# I2C register map
Vendor: Texas Instruments
Peripheral module from a debugger description file (folder am335x).
Registers are 32-bit, access per field, no defined reset value unless marked. A register's access mark holds for its fields unless they carry their own. Offsets are as the file gives them; lines under a group give offsets from that group; [hi:lo] are bit positions; {n}, {i} and the like mark numbered series; 'fields as' and 'values as' point back to an identical list; <NAME> marks a mode.

## I2C (part 1 of 2)
0x38 I2C_DMARXENABLE_SET — The 1-bit field enables a receive DMA request. Writing a 1 to this field will set it to 1. Writing a 0 will have no effect, that is, the register value is not modified. Note that the I2C_BUF.RDMA_EN field is the global (slave) DMA enabler, and that it is disabled by default. The I2C_BUF.RDMA_EN field should also be set to 1 to enable a receive DMA request.
  [0] DMARX_ENABLE_SET rw — Receive DMA channel enable set.
0x3C I2C_DMATXENABLE_SET — The 1-bit field enables a transmit DMA request. Writing a 1 to this field will set it to 1. Writing a 0 will have no effect, that is, the register value is not modified. Note that the I2C_BUF.XDMA_EN field is the global (slave) DMA enabler, and that it is disabled by default. The I2C_BUF.XDMA_EN field should also be set to 1 to enable a transmit DMA request.
  [0] DMATX_TRANSMIT_SET rw — Transmit DMA channel enable set.
0x40 I2C_DMARXENABLE_CLR — The 1-bit field disables a receive DMA request. Writing a 1 to a bit will clear it to 0. Another result of setting to 1 the DMARX_ENABLE_CLEAR field, is the reset of the DMA RX request and wakeup lines. Writing a 0 will have no effect, that is, the register value is not modified.
  [0] DMARX_ENABLE_CLEAR rw — Receive DMA channel enable clear.
0x44 I2C_DMATXENABLE_CLR — The 1-bit field disables a transmit DMA request. Writing a 1 to a bit will clear it to 0. Another result of setting to 1 the DMATX_ENABLE_CLEAR field, is the reset of the DMA TX request and wakeup lines. Writing a 0 will have no effect, that is, the register value is not modified.
  [0] DMARX_ENABLE_CLEAR rw — Receive DMA channel enable clear.
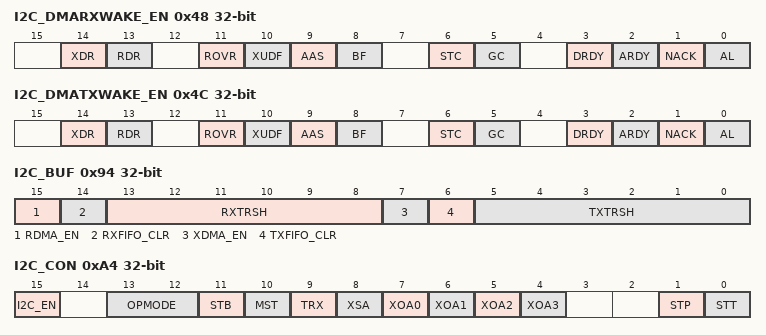
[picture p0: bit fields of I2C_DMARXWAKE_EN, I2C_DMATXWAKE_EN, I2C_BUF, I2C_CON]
0x48 I2C_DMARXWAKE_EN — All 1-bit fields enable a specific (synchronous) DMA request source to generate an asynchronous wakeup (on the appropriate swakeup line). Note that the I2C_SYSC.ENAWAKEUP field is the global (slave) wakeup enabler, and that it is disabled by default.
  [14] XDR rw — Transmit draining wakeup set.
  [13] RDR rw — Receive draining wakeup set.
  [11] ROVR rw — Receive overrun wakeup set.
  [10] XUDF rw — Transmit underflow wakeup set.
  [9] AAS rw — Address as slave IRQ wakeup set.
  [8] BF rw — Bus free IRQ wakeup set.
  [6] STC rw — Start condition IRQ wakeup set.
  [5] GC rw — General call IRQ wakeup set.
  [3] DRDY rw — Receive/transmit data ready IRQ wakeup set.
  [2] ARDY rw — Register access ready IRQ wakeup set.
  [1] NACK rw — No acknowledgment IRQ wakeup set.
  [0] AL rw — Arbitration lost IRQ wakeup set.
0x4C I2C_DMATXWAKE_EN — All 1-bit fields enable a specific (synchronous) DMA request source to generate an asynchronous wakeup (on the appropriate swakeup line). Note that the I2C_SYSC.ENAWAKEUP field is the global (slave) wakeup enabler, and that it is disabled by default.
  fields as I2C_DMARXWAKE_EN
0x90 I2C_SYSS
  [0] RDONE rw — Reset done bit. This read-only bit indicates the state of the reset in case of hardware reset, global software reset (I2C_SYSC.SRST) or partial software reset (I2C_CON.I2C_EN). The module must receive all its clocks before it can grant a reset-completed status. Value after reset is low.
0x94 I2C_BUF — This read/write register enables DMA transfers and allows the configuration of FIFO thresholds for the FIFO management (see the FIFO Management subsection).
  [15] RDMA_EN rw — Receive DMA channel enable. When this bit is set to 1, the receive DMA channel is enabled and the receive data ready status bit (I2C_IRQSTATUS_RAW: RRDY) is forced to 0 by the core. Value after reset is low.
  [14] RXFIFO_CLR rw — Receive FIFO clear. When set, receive FIFO is cleared (hardware reset for RX FIFO generated). This bit is automatically reset by the hardware. During reads, it always returns 0. Value after reset is low.
  [13:8] RXTRSH rw — Threshold value for FIFO buffer in RX mode. The receive threshold value is used to specify the trigger level for data receive transfers. The value is specified from the Interface/OCP point of view. Value after reset is 00h. For the FIFO management description, see the FIFO Management subsection. Note 1: programmed threshold cannot exceed the actual depth of the FIFO. Note 2: the threshold must not be changed while a transfer is in progress (after STT was configured or after the module was addressed as a slave).
  [7] XDMA_EN rw — Transmit DMA channel enable. When this bit is set to 1, the transmit DMA channel is enabled and the transmit data ready status (I2C_IRQSTATUS_RAW: XRDY) bit is forced to 0 by the core. Value after reset is low.
  [6] TXFIFO_CLR rw — Transmit FIFO clear. When set, transmit FIFO is cleared (hardware reset for TX FIFO). This bit is automatically reset by the hardware. During reads, it always returns 0. Value after reset is low.
  [5:0] TXTRSH rw — Threshold value for FIFO buffer in TX mode. The Transmit Threshold value is used to specify the trigger level for data transfers. The value is specified from the OCP point of view. Value after reset is 00h Note 1: programmed threshold cannot exceed the actual depth of the FIFO. Note 2: the threshold must not be changed while a transfer is in progress (after STT was configured or after the module was addressed as a slave).
0x98 I2C_CNT — CAUTION: During an active transfer phase (between STT having been set to 1 and reception of ARDY), no modification must be done in this register. Changing it may result in an unpredictable behavior. This read/write register is used to control the numbers of bytes in the I2C data payload.
  [15:0] DCOUNT rw — Data count. I2C Master Mode only (receive or transmit; F/S). This 16-bit countdown counter decrements by 1 for every byte received or sent through the I2C interface. A write initializes DCOUNT to a saved initial value. A read returns the number of bytes that are yet to be received or sent. A read into DCOUNT returns the initial value only before a start condition and after a stop condition. When DCOUNT reaches 0, the core generates a stop condition if a stop condition was specified (I2C_CON.STP = 1) and the ARDY status flag is set to 1 in the I2C_IRQSTATUS_RAW register. Note that DCOUNT must not be reconfigured after I2C_CON.STT was enabled and before ARDY is received. Note 1: In case of I2C mode of operation, if I2C_CON.STP = 0, then the I2C asserts SCL = 0 when DCOUNT reaches 0. The CPU can then reprogram DCOUNT to a new value and resume sending or receiving data with a new start condition (restart). This process repeats until the CPU sets to 1 the I2C_CON.STP bit. The ARDY flag is set each time DCOUNT reaches 0 and DCOUNT is reloaded to its initial value. Values after reset are low (all 16 bits). Note 2: Since for DCOUNT = 0, the transfer length is 65536, the module does not allow the possibility to initiate zero data bytes transfers.
0x9C I2C_DATA — This register is the entry point for the local host to read data from or write data to the FIFO buffer.
  [7:0] DATA rw — Transmit/Receive data FIFO endpoint. When read, this register contains the received I2C data. When written, this register contains the byte value to transmit over the I2C data. In SYSTEST loop back mode (I2C_SYSTEST: TMODE = 11), this register is also the entry/receive point for the data. Values after reset are unknown (all 8-bits). Note: A read access, when the buffer is empty, returns the previous read data value. A write access, when the buffer is full, is ignored. In both events, the FIFO pointers are not updated and an Access Error (AERR) Interrupt is generated.
0xA4 I2C_CON — During an active transfer phase (between STT having been set to 1 and reception of ARDY), no modification must be done in this register (except STP enable). Changing it may result in an unpredictable behavior.
  [15] I2C_EN rw — I2C module enable. When this bit is cleared to 0, the I2C controller is not enabled and reset. When 0, receive and transmit FIFOs are cleared and all status bits are set to their default values. All configuration registers (I2C_IRQENABLE_SET, I2C_IRQWAKE_SET, I2C_BUF, I2C_CNT, I2C_CON, I2C_OA, I2C_SA, I2C_PSC, I2C_SCLL and I2C_SCLH) are not reset, they keep their initial values and can be accessed. The CPU must set this bit to 1 for normal operation. Value after reset is low.
  [13:12] OPMODE rw — Operation mode selection. These two bits select module operation mode. Value after reset is 00.
  [11] STB rw — Start byte mode (I2C master mode only). The start byte mode bit is set to 1 by the CPU to configure the I2C in start byte mode (I2C_SA = 0000 0001). See the Philips I2C spec for more details [1]. Value after reset is low.
  [10] MST rw — Master/slave mode (I2C mode only). When this bit is cleared, the I2C controller is in the slave mode and the serial clock (SCL) is received from the master device. When this bit is set, the I2C controller is in the master mode and generates the serial clock. Note: This bit is automatically cleared at the end of the transfer on a detected stop condition, in case of arbitration lost or when the module is configured as a master but addressed as a slave by an external master. Value after reset is low.
  [9] TRX rw — Transmitter/receiver mode (i2C master mode only). When this bit is cleared, the I2C controller is in the receiver mode and data on data line SDA is shifted into the receiver FIFO and can be read from I2C_DATA register. When this bit is set, the I2C controller is in the transmitter mode and the data written in the transmitter FIFO via I2C_DATA is shifted out on data line SDA. Value after reset is low. The operating modes are defined as follows: MST = 0, TRX = x, Operating Mode = Slave receiver. MST = 0, TRX = x, Operating Mode = Slave transmitter. MST = 1, TRX = 0, Operating Modes = Master receiver. MST = 1, TRX = 0, Operating Modes = Master transmitter.
  [8] XSA rw — Expand slave address. (I2C mode only). When set, this bit expands the slave address to 10-bit. Value after reset is low.
  [7] XOA0 rw — Expand own address 0. (I2C mode only). When set, this bit expands the base own address (OA0) to 10-bit. Value after reset is low.
  [6] XOA1 rw — Expand own address 1. (I2C mode only). When set, this bit expands the first alternative own address (OA1) to 10-bit. Value after reset is low.
  [5] XOA2 rw — Expand own address 2. (I2C mode only). When set, this bit expands the second alternative own address (OA2) to 10-bit. Value after reset is low.
  [4] XOA3 rw — Expand own address 3. When set, this bit expands the third alternative own address (OA3) to 10-bit. Value after reset is low.
  [1] STP rw — Stop condition (I2C master mode only). This bit can be set to a 1 by the CPU to generate a stop condition. It is reset to 0 by the hardware after the stop condition has been generated. The stop condition is generated when DCOUNT passes 0. When this bit is not set to 1 before the end of the transfer (DCOUNT = 0), the stop condition is not generated and the SCL line is hold to 0 by the master, which can re-start a new transfer by setting the STT bit to 1. Value after reset is low
  [0] STT rw — Start condition (I2C master mode only). This bit can be set to a 1 by the CPU to generate a start condition. It is reset to 0 by the hardware after the start condition has been generated. The start/stop bits can be configured to generate different transfer formats. Value after reset is low. Note: DCOUNT is data count value in I2C_CNT register. STT = 1, STP = 0, Conditions = Start, Bus Activities = S-A-D. STT = 0, STP = 1, Conditions = Stop, Bus Activities = P. STT = 1, STP = 1, Conditions = Start-Stop (DCOUNT=n), Bus Activities = S-A-D..(n)..D-P. STT = 1, STP = 0, Conditions = Start (DCOUNT=n), Bus Activities = S-A-D..(n)..D.
0xA8 I2C_OA — CAUTION: During an active transfer phase (between STT having been set to 1 and reception of ARDY), no modification must be done in this register. Changing it may result in an unpredictable behavior. This register is used to specify the module s base I2C 7-bit or 10-bit address (base own address).
  [9:0] OA rw — Own address. This field specifies either: A 10-bit address coded on OA [9:0] when XOA (Expand Own Address, I2C_CON[7]) is set to 1. or A 7-bit address coded on OA [6:0] when XOA (Expand Own Address, I2C_CON[7]) is cleared to 0. In this case, OA [9:7] bits must be cleared to 000 by application software. Value after reset is low (all 10 bits).
0xAC I2C_SA — CAUTION: During an active transfer phase (between STT having been set to 1 and reception of ARDY), no modification must be done in this register. Changing it may result in an unpredictable behavior. This register is used to specify the addressed I2C module 7-bit or 10-bit address (slave address).
  [9:0] SA rw — Slave address. This field specifies either: A 10-bit address coded on SA [9:0] when XSA (Expand Slave Address, I2C_CON[8]) is set to 1. or A 7-bit address coded on SA [6:0] when XSA (Expand Slave Address, I2C_CON[8]) is cleared to 0. In this case, SA [9:7] bits must be cleared to 000 by application software. Value after reset is low (all 10 bits).
0xB0 I2C_PSC — CAUTION: During an active mode (I2C_EN bit in I2C_CON register is set to 1), no modification must be done in this register. Changing it may result in an unpredictable behavior. This register is used to specify the internal clocking of the I2C peripheral core.
  [7:0] PSC rw — Fast/Standard mode prescale sampling clock divider value. The core uses this 8-bit value to divide the system clock (SCLK) and generates its own internal sampling clock (ICLK) for Fast and Standard operation modes. The core logic is sampled at the clock rate of the system clock for the module divided by (PSC + 1). Value after reset is low (all 8 bits).
0xB4 I2C_SCLL — CAUTION: During an active mode (I2C_EN bit in I2C_CON register is set to 1), no modification must be done in this register. Changing it may result in an unpredictable behavior. This register is used to determine the SCL low time value when master.
  [7:0] SCLL rw — Fast/Standard mode SCL low time. I2C master mode only, (FS). This 8-bit value is used to generate the SCL low time value (tLOW) when the peripheral is operated in master mode. tLOW = (SCLL + 7) * ICLK time period, Value after reset is low (all 8 bits).
0xB8 I2C_SCLH — CAUTION: During an active mode (I2C_EN bit in I2C_CON register is set to 1), no modification must be done in this register. Changing it may result in an unpredictable behavior. This register is used to determine the SCL high time value when master.
  [7:0] SCLH rw — Fast/Standard mode SCL low time. I2C master mode only, (FS). This 8-bit value is used to generate the SCL high time value (tHIGH) when the peripheral is operated in master mode. - tHIGH = (SCLH + 5) * ICLK time period. Value after reset is low (all 8 bits).
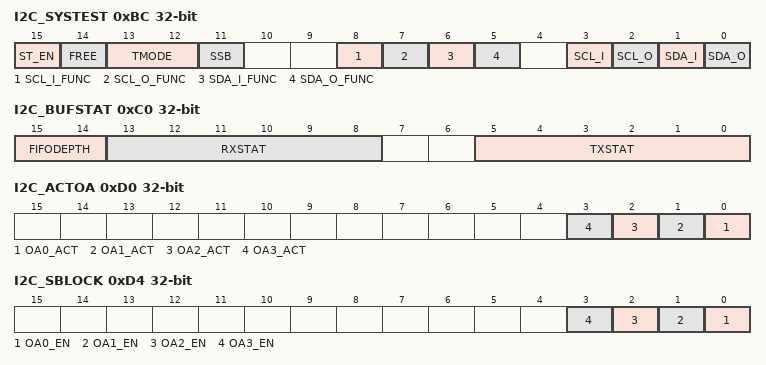
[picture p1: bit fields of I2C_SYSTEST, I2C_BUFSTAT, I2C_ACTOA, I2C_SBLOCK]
0xBC I2C_SYSTEST — CAUTION: Never enable this register for normal I2C operation This register is used to facilitate system-level tests by overriding some of the standard functional features of the peripheral. It allows testing of SCL counters, controlling the signals that connect to I/O pins, or creating digital loop-back for self-test when the module is configured in system test (SYSTEST) mode. It also provides stop/non-stop functionality in the debug mode.
  [15] ST_EN rw — System test enable. This bit must be set to 1 to permit other system test registers bits to be set. Value after reset is low.
  [14] FREE rw — Free running mode (on breakpoint). This bit is used to determine the state of the I2C controller when a breakpoint is encountered in the HLL debugger. Note: This bit can be set independently of ST_EN value. FREE = 0: the I2C controller stops immediately after completion of the on-going bit transfer. Stopping the transfer is achieved by forcing the SCL line low. Note that in this case there will be no status register updates. FREE = 1: the I2C interface runs free. When Suspend indication will be asserted, there will be no accesses on the OCP Interface (the CPU is in debug mode) and consequently the FIFOs will reach full/empty state (according to RX or TX modes) and the I2C SDA line will be kept low. Note that the status registers will be updated, but no DMA, IRQ or WakeUp will be generated. The status registers likely to be updated in this mode are: I2C_IRQSTATUS_RAW.XRDY, I2C_IRQSTATUS_RAW.RRDY, I2C_IRQSTATUS_RAW.XUDF, I2C_IRQSTATUS_RAW.ROVR, I2C_IRQSTATUS_RAW.ARDY and I2C_IRQSTATUS_RAW.NACK. Value after reset is low.
  [13:12] TMODE rw — Test mode select. In normal functional mode (ST_EN = 0), these bits are don't care. They are always read as 00 and a write is ignored. In system test mode (ST_EN = 1), these bits can be set according to the following table to permit various system tests. Values after reset are low (2 bits). SCL counter test mode: in this mode, the SCL pin is driven with a permanent clock as if mastered with the parameters set in the I2C_PSC, I2C_SCLL, and I2C_SCLH registers. Loop back mode: in the master transmit mode only, data transmitted out of the I2C_DATA register (write action) is received in the same I2C_DATA register via an internal path through the FIFO buffer. The DMA and interrupt requests are normally generated if enabled. SDA/SCL IO mode: in this mode, the SCL IO and SDA IO are controlled via the I2C_SYSTEST [5:0] register bits.
  [11] SSB rw — Set status bits. Writing 1 into this bit also sets the 6 read/clear-only status bits contained in I2C_IRQSTATUS_RAW register (bits 5:0) to 1. Writing 0 into this bit doesn't clear status bits that are already set; only writing 1 into a set status bit can clear it (see I2C_IRQSTATUS_RAW operation). This bit must be cleared prior attempting to clear a status bit. Value after reset is low.
  [8] SCL_I_FUNC ro — SCL line input value (functional mode). This read-only bit returns the logical state taken by the SCL line (either 1 or 0). It is active both in functional and test mode. Value after reset is low.
  [7] SCL_O_FUNC ro — SCL line output value (functional mode). This read-only bit returns the value driven by the module on the SCL line (either 1 or 0). It is active both in functional and test mode. Value after reset is low.
  [6] SDA_I_FUNC ro — SDA line input value (functional mode). This read-only bit returns the logical state taken by the SDA line (either 1 or 0). It is active both in functional and test mode. Value after reset is low.
  [5] SDA_O_FUNC ro — SDA line output value (functional mode). This read-only bit returns the value driven by the module on the SDA line (either 1 or 0). It is active both in functional and test mode. Value after reset is low.
  [3] SCL_I ro — SCL line sense input value. In normal functional mode (ST_EN = 0), this read-only bit always reads 0. In system test mode (ST_EN = 1 and TMODE = 11), this read-only bit returns the logical state taken by the SCL line (either 1 or 0). Value after reset is low.
  [2] SCL_O ro — SCL line drive output value. In normal functional mode (ST_EN = 0), this bit is don't care. It always reads 0 and a write is ignored. In system test mode (ST_EN = 1 and TMODE = 11), a 0 forces a low level on the SCL line and a 1 puts the I2C output driver to a high-impedance state. Value after reset is low.
  [1] SDA_I ro — SDA line sense input value. In normal functional mode (ST_EN = 0), this read-only bit always reads 0. In system test mode (ST_EN = 1 and TMODE = 11), this read-only bit returns the logical state taken by the SDA line (either 1 or 0). Value after reset is low.
  [0] SDA_O ro — SDA line drive output value. In normal functional mode (ST_EN = 0), this bit is don't care. It reads as 0 and a write is ignored. In system test mode (ST_EN = 1 and TMODE = 11), a 0 forces a low level on the SDA line and a 1 puts the I2C output driver to a high-impedance state. Value after reset is low.
0xC0 I2C_BUFSTAT ro — This read-only register reflects the status of the internal buffers for the FIFO management (see the FIFO Management subsection).
  [15:14] FIFODEPTH — Internal FIFO buffers depth. This read-only bit indicates the internal FIFO buffer depth. Value after reset is given by the boundary module generic parameter.
  [13:8] RXSTAT — RX buffer status. This read-only field indicates the number of bytes to be transferred from the FIFO at the end of the I2C transfer (when RDR is asserted). It corresponds to the level indication of the RX FIFO (number of written locations). Value after reset is 0.
  [5:0] TXSTAT — TX buffer status. This read-only field indicates the number of data bytes still left to be written in the TX FIFO (it s equal with the initial value of I2C_CNT.DCOUNT minus the number of data bytes already written in the TX FIFO through the OCP Interface). Value after reset is equal with 0.
0xC4 I2C_OA1 — CAUTION: During an active transfer phase (between STT has been set to 1 and receiving of ARDY), no modification must be done in this register. Changing it may result in an unpredictable behavior. This register is used to specify the first alternative I2C 7-bit or 10-bit address (own address 1 - OA1).
  [9:0] OA1 rw — Own address 1. This field specifies either: A 10-bit address coded on OA1 [9:0] when XOA1 (Expand Own Address 1 - XOA1, I2C_CON[6]) is set to 1. A 7-bit address coded on OA1 [6:0] when XOA1 (Expand Own Address 1 XOA1, I2C_CON[6]) is cleared to 0. In this case, OA1 [9:7] bits must be cleared to 000 by application software. Value after reset is low (all 10 bits).
0xC8 I2C_OA2 — CAUTION: During an active transfer phase (between STT has been set to 1 and receiving of ARDY), no modification must be done in this register. Changing it may result in an unpredictable behavior. This register is used to specify the first alternative I2C 7-bit or 10-bit address (own address 2 - OA2).
  [9:0] OA2 rw — Own address 2. This field specifies either: A 10-bit address coded on OA2 [9:0] when XOA1 (Expand Own Address 2 - XOA2, I2C_CON[5]) is set to 1. A 7-bit address coded on OA2 [6:0] when XOA2 (Expand Own Address 2 XOA2, I2C_CON[5]) is cleared to 0. In this case, OA2 [9:7] bits must be cleared to 000 by application software. Value after reset is low (all 10 bits).
0xCC I2C_OA3 — CAUTION: During an active transfer phase (between STT has been set to 1 and receiving of ARDY), no modification must be done in this register. Changing it may result in an unpredictable behavior. This register is used to specify the first alternative I2C 7-bit or 10-bit address (own address 3 - OA3).
  [9:0] OA3 rw — Own address 2. This field specifies either: A 10-bit address coded on OA3 [9:0] when XOA3 (Expand Own Address 3 - XOA3, I2C_CON[4]) is set to 1. A 7-bit address coded on OA3 [6:0] when XOA1 (Expand Own Address 3 XOA3, I2C_CON[4]) is cleared to 0. In this case, OA3 [9:7] bits must be cleared to 000 by application software. Value after reset is low (all 10 bits).
0xD0 I2C_ACTOA ro — This read-only register is used to indicate which one of the module s four own addresses the external master used when addressing the module. The CPU can read this register when the AAS indication was activated. The indication is cleared at the end of the transfer.
  [n] OA{n}_ACT (n=0..3) — Own address {n} active. When a bit location is set to 1 by the core, it signalizes to the Local Host that an external master using the corresponding own address addressed the module. Value after reset is low.
0xD4 I2C_SBLOCK — This read/write register controls the automatic blocking of I2C clock feature in slave mode. It is used for the Local Host to configure for which of the 4 own addresses, the core must block the I2C clock (keep SCL line low) right after the Address Phase, when it is addressed as a slave.
  [n] OA{n}_EN rw (n=0..3) — Enable I2C clock blocking for own address {n}. When the CPU sets a bit location to 1, if an external master using the corresponding own address addresses the core, the core will block the I2C clock right after the address phase. For releasing the I2C clock the CPU must write 0 in the corresponding field. Value after reset is low.
